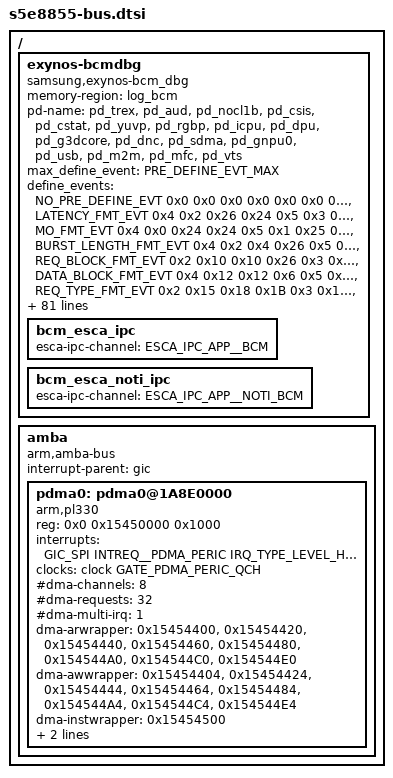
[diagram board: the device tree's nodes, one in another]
/* 
 * SAMSUNG S5E8855 SoC bus device tree source
 *
 * Copyright (c) 2024 Samsung Electronics Co., Ltd.
 *		http://www.samsung.com
 *
 * SAMSUNG S5E8855 SoC bus device nodes are listed in this file.
 * EXYNOS based board files should include this file.
 *
 * This program is free software; you can redistribute it and/or modify
 * it under the terms of the GNU General Public License version 2 as
 * published by the Free Software Foundation.
 *
 */

#include <dt-bindings/soc/samsung/exynos-bcm_dbg.h>
#include "s5e8855-bts.dtsi"

/ {
	exynos-bcmdbg {
		compatible = "samsung,exynos-bcm_dbg";
		memory-region = <&log_bcm>;

		pd-name = "pd_trex", "pd_aud", "pd_nocl1b", "pd_csis",  "pd_cstat",
			"pd_yuvp", "pd_rgbp", "pd_icpu", "pd_dpu", "pd_g3dcore",
			"pd_dnc", "pd_sdma", "pd_gnpu0", "pd_usb", "pd_m2m", "pd_mfc", "pd_vts";
		max_define_event = <PRE_DEFINE_EVT_MAX>;
		/* define_event_index ev0 ev1 ev2 ev3 ev4 ev5 ev6 ev7 */
		define_events = <NO_PRE_DEFINE_EVT	0x0  0x0  0x0  0x0  0x0  0x0  0x0  0x0>,
				<LATENCY_FMT_EVT	0x4  0x2  0x26 0x24 0x5  0x3  0x27 0x25>,
				<MO_FMT_EVT		0x4  0x0  0x24 0x24 0x5  0x1  0x25 0x25>,
				<BURST_LENGTH_FMT_EVT	0x4  0x2  0x4  0x26 0x5  0x3  0x5  0x27>,
				<REQ_BLOCK_FMT_EVT	0x2  0x10 0x10 0x26 0x3  0x11 0x11 0x27>,
				<DATA_BLOCK_FMT_EVT	0x4  0x12 0x12 0x6  0x5  0x13 0x13 0x14>,
				<REQ_TYPE_FMT_EVT	0x2  0x15 0x18 0x1B 0x3  0x16 0x19 0x1C>,
				<BW_DFP_FMT_EVT		0x4  0x2  0x2A 0x24 0x5  0x3  0x2B 0x25>,
				<BCM_CALC_FMT_EVT	0x4  0x5  0x26 0x24 0x0  0x1  0x27 0x25>;
		default_define_event = <LATENCY_FMT_EVT>;

		/* sm_id_mask sm_id_value */
		define_filter_id = <NO_PRE_DEFINE_EVT	0x0  0x0>,
				<LATENCY_FMT_EVT	0x0  0x0>,
				<MO_FMT_EVT		0x0  0x0>,
				<BURST_LENGTH_FMT_EVT	0x0  0x0>,
				<REQ_BLOCK_FMT_EVT	0x0  0x0>,
				<DATA_BLOCK_FMT_EVT	0x0  0x0>,
				<REQ_TYPE_FMT_EVT	0x0  0x0>,
				<BW_DFP_FMT_EVT		0x0  0x0>,
				<BCM_CALC_FMT_EVT	0x0  0x0>;
		/* ev0 ev1 ev2 ev3 ev4 ev5 ev6 ev7 */
		define_filter_id_active = <NO_PRE_DEFINE_EVT	0x0  0x0  0x0  0x0  0x0  0x0  0x0  0x0>,
					<LATENCY_FMT_EVT	0x0  0x0  0x0  0x0  0x0  0x0  0x0  0x0>,
					<MO_FMT_EVT		0x0  0x0  0x0  0x0  0x0  0x0  0x0  0x0>,
					<BURST_LENGTH_FMT_EVT	0x0  0x0  0x0  0x0  0x0  0x0  0x0  0x0>,
					<REQ_BLOCK_FMT_EVT	0x0  0x0  0x0  0x0  0x0  0x0  0x0  0x0>,
					<DATA_BLOCK_FMT_EVT	0x0  0x0  0x0  0x0  0x0  0x0  0x0  0x0>,
					<REQ_TYPE_FMT_EVT	0x0  0x0  0x0  0x0  0x0  0x0  0x0  0x0>,
					<BW_DFP_FMT_EVT		0x0  0x0  0x0  0x0  0x0  0x0  0x0  0x0>,
					<BCM_CALC_FMT_EVT	0x0  0x0  0x0  0x0  0x0  0x0  0x0  0x0>;
		/* sm_other_type0 sm_other_mask0 sm_other_value0 */
		define_filter_other_0 = <NO_PRE_DEFINE_EVT	0x0  0x0  0x0>,
					<LATENCY_FMT_EVT	0x0  0x0  0x0>,
					<MO_FMT_EVT		0x0  0x0  0x0>,
					<BURST_LENGTH_FMT_EVT	0x0  0x0  0x0>,
					<REQ_BLOCK_FMT_EVT	0x0  0x0  0x0>,
					<DATA_BLOCK_FMT_EVT	0x0  0x0  0x0>,
					<REQ_TYPE_FMT_EVT	0x0  0x0  0x0>,
					<BW_DFP_FMT_EVT		0x0  0x0  0x0>,
					<BCM_CALC_FMT_EVT	0x0  0x0  0x0>;
		/* sm_other_type1 sm_other_mask1 sm_other_value1 */
		define_filter_other_1 = <NO_PRE_DEFINE_EVT	0x0  0x0  0x0>,
					<LATENCY_FMT_EVT	0x0  0x0  0x0>,
					<MO_FMT_EVT		0x0  0x0  0x0>,
					<BURST_LENGTH_FMT_EVT	0x0  0x0  0x0>,
					<REQ_BLOCK_FMT_EVT	0x0  0x0  0x0>,
					<DATA_BLOCK_FMT_EVT	0x0  0x0  0x0>,
					<REQ_TYPE_FMT_EVT	0x0  0x0  0x0>,
					<BW_DFP_FMT_EVT		0x0  0x0  0x0>,
					<BCM_CALC_FMT_EVT	0x0  0x0  0x0>;
		/* ev0 ev1 ev2 ev3 ev4 ev5 ev6 ev7 */
		define_filter_other_active = <NO_PRE_DEFINE_EVT	0x0  0x0  0x0  0x0  0x0  0x0  0x0  0x0>,
					<LATENCY_FMT_EVT	0x0  0x0  0x0  0x0  0x0  0x0  0x0  0x0>,
					<MO_FMT_EVT		0x0  0x0  0x0  0x0  0x0  0x0  0x0  0x0>,
					<BURST_LENGTH_FMT_EVT	0x0  0x0  0x0  0x0  0x0  0x0  0x0  0x0>,
					<REQ_BLOCK_FMT_EVT	0x0  0x0  0x0  0x0  0x0  0x0  0x0  0x0>,
					<DATA_BLOCK_FMT_EVT	0x0  0x0  0x0  0x0  0x0  0x0  0x0  0x0>,
					<REQ_TYPE_FMT_EVT	0x0  0x0  0x0  0x0  0x0  0x0  0x0  0x0>,
					<BW_DFP_FMT_EVT		0x0  0x0  0x0  0x0  0x0  0x0  0x0  0x0>,
					<BCM_CALC_FMT_EVT	0x0  0x0  0x0  0x0  0x0  0x0  0x0  0x0>;
		/* peak_mask peak_id */
		define_sample_id = <NO_PRE_DEFINE_EVT	0x0  0x0>,
				<LATENCY_FMT_EVT	0x0  0x0>,
				<MO_FMT_EVT		0x0  0x0>,
				<BURST_LENGTH_FMT_EVT	0x0  0x0>,
				<REQ_BLOCK_FMT_EVT	0x0  0x0>,
				<DATA_BLOCK_FMT_EVT	0x0  0x0>,
				<REQ_TYPE_FMT_EVT	0x0  0x0>,
				<BW_DFP_FMT_EVT		0x0  0x0>,
				<BCM_CALC_FMT_EVT	0x0  0x0>;
		/* ev0 ev1 ev2 ev3 ev4 ev5 ev6 ev7 */
		define_sample_id_enable = <NO_PRE_DEFINE_EVT	0x0  0x0  0x0  0x0  0x0  0x0  0x0  0x0>,
					<LATENCY_FMT_EVT	0x0  0x0  0x1  0x0  0x0  0x0  0x1  0x0>,
					<MO_FMT_EVT		0x0  0x0  0x1  0x0  0x0  0x0  0x1  0x0>,
					<BURST_LENGTH_FMT_EVT	0x0  0x0  0x1  0x1  0x0  0x0  0x1  0x1>,
					<REQ_BLOCK_FMT_EVT	0x0  0x0  0x1  0x1  0x0  0x0  0x1  0x1>,
					<DATA_BLOCK_FMT_EVT	0x0  0x0  0x1  0x0  0x0  0x0  0x1  0x0>,
					<REQ_TYPE_FMT_EVT	0x0  0x0  0x0  0x0  0x0  0x0  0x0  0x0>,
					<BW_DFP_FMT_EVT		0x0  0x0  0x0  0x0  0x0  0x0  0x0  0x0>,
					<BCM_CALC_FMT_EVT	0x0  0x0  0x0  0x0  0x0  0x0  0x0  0x0>;

		bcm_cnt_nr = <8>;
		bcm_ip_nr = <42>;
		bcm_ip_print_nr = <10>;
		unused_bcm_ip = <>;
		initial_bcm_run = <BCM_STOP>;
		/* msec (max 500msec) */
		initial_period = <1000>;
		initial_bcm_mode = <BCM_MODE_INTERVAL>;
		available_stop_owner = <PANIC_HANDLE CAMERA_DRIVER MODEM_IF ITMON_HANDLE>;
		halt_owner = <PANIC_HANDLE ITMON_HANDLE>;
		glb_auto_en = <0>;

		rtc_addr = <0x11910000>, <0x90>;

		bcm_esca_ipc {
			esca-ipc-channel = <ESCA_IPC_APP__BCM>;
		};
		bcm_esca_noti_ipc {
			esca-ipc-channel = <ESCA_IPC_APP__NOTI_BCM>;
		};
	};

	/* DMA */
	amba {
		#address-cells = <2>;
		#size-cells = <1>;
		compatible = "arm,amba-bus";
		interrupt-parent = <&gic>;
		ranges;
		pdma0: pdma0@1A8E0000 {
			compatible = "arm,pl330", "arm,primecell";
			reg = <0x0 0x15450000 0x1000>;
			interrupts = <GIC_SPI INTREQ__PDMA_PERIC IRQ_TYPE_LEVEL_HIGH>;
			clocks = <&clock GATE_PDMA_PERIC_QCH>;
			clock-names = "apb_pclk";
			#dma-cells = <1>;
			#dma-channels = <8>;
			#dma-requests = <32>;
			#dma-multi-irq = <1>;
			dma-arwrapper = <0x15454400>,
					<0x15454420>,
					<0x15454440>,
					<0x15454460>,
					<0x15454480>,
					<0x154544A0>,
					<0x154544C0>,
					<0x154544E0>;
			dma-awwrapper = <0x15454404>,
					<0x15454424>,
					<0x15454444>,
					<0x15454464>,
					<0x15454484>,
					<0x154544A4>,
					<0x154544C4>,
					<0x154544E4>;
			dma-instwrapper = <0x15454500>;
			dma-mask-bit = <36>;
			coherent-mask-bit = <36>;
		};
	};
};

